# WKUP_CTRL_MMR0_WKUP_CTRL_MMR0_DDR_FREQ_CHG_43040000h register map
Vendor: Texas Instruments
Peripheral module from a debugger description file (folder am62L).
Registers are 32-bit, read-write, reset 0x0 unless marked. A register's access mark holds for its fields unless they carry their own. Offsets are as the file gives them; lines under a group give offsets from that group; [hi:lo] are bit positions; {n}, {i} and the like mark numbered series; 'fields as' and 'values as' point back to an identical list; <NAME> marks a mode.

## WKUP_CTRL_MMR0_DDR_FREQ_CHG
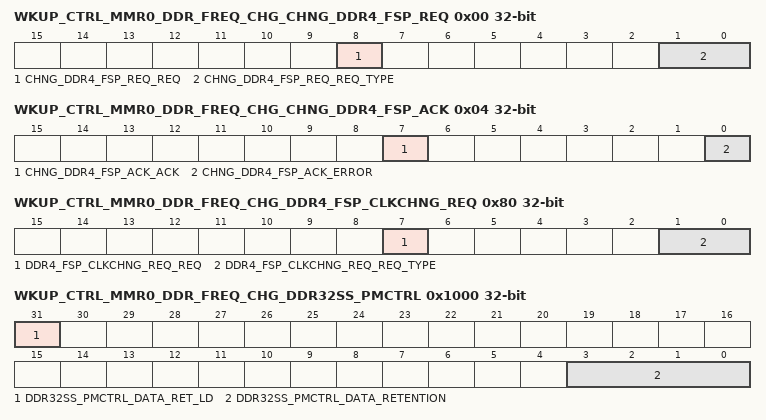
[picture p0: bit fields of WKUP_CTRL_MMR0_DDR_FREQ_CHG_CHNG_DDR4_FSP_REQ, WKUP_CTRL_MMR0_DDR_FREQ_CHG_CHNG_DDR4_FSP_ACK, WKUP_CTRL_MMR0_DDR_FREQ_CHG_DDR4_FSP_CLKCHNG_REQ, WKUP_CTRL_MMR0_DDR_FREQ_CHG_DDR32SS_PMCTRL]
0x00 WKUP_CTRL_MMR0_DDR_FREQ_CHG_CHNG_DDR4_FSP_REQ — This register is used to initiate a LPDDR4 frequency set point change to the DDR Controller
  [8] CHNG_DDR4_FSP_REQ_REQ — Initiate FSP frequency change 0 INACTIVE1 ACTIVE
  [1:0] CHNG_DDR4_FSP_REQ_REQ_TYPE — Frequency request type - Desired Frequency Set Point after switch. 0 FSP01 FSP12 FSP23 FSP3
0x04 WKUP_CTRL_MMR0_DDR_FREQ_CHG_CHNG_DDR4_FSP_ACK ro — This register is used by the DDR Controller to acknowledge the LPDDR4 frequency set point shange request
  [7] CHNG_DDR4_FSP_ACK_ACK — Frequency change acknowledge.This bit is only valid when CHNG_DDR4_FSP_REQ_req is activeIndication from the DDR Controller that the Frequency Set Point change operation is complete 0 IN_PROGRESS1 COMPLETE
  [0] CHNG_DDR4_FSP_ACK_ERROR — Frequency change errorThis bit is only valid when CHNG_DDR4_FSP_REQ_req is active. 0 SUCCESS1 ERROR
0x80 WKUP_CTRL_MMR0_DDR_FREQ_CHG_DDR4_FSP_CLKCHNG_REQ ro — This register is used by the DDR Controller to request the DDR PLL clock frequency change. This can occur as part of DDR4 initialization and training or in response to a LPDDR4 FSP change request.
  [7] DDR4_FSP_CLKCHNG_REQ_REQ — DDR Controller FSP clock change requestIndicates that the DDR controller needs the DDR clock changed to the frequency set point indicated by the req_type field. This bit is cleared when the DDR4_FSP_CLKCHNG_ACK_ack bit is set. 0 INACTIVE1 ACTIVE
  [1:0] DDR4_FSP_CLKCHNG_REQ_REQ_TYPE — Frequency request type - Desired Frequency Set Point after switch. 0 FSP01 FSP12 FSP23 FSP3
0x84 WKUP_CTRL_MMR0_DDR_FREQ_CHG_DDR4_FSP_CLKCHNG_ACK — This register is used to acknowledge a DDR PLL clock frequency change to the DDR Controller.
  [0] DDR4_FSP_CLKCHNG_ACK_ACK — DDR FSP clock change ackowledgeThis bit should be set once the DDR clock has been sucessfully changed to the value requested by DDR4_FSP_CLKCHNG_REQ_req_type. Setting this bit will clear the DDR4_FSP_CLKCHNG_REQ_req bit and the associated change request interrupt. 1 COMPLETE
0x1000 WKUP_CTRL_MMR0_DDR_FREQ_CHG_DDR32SS_PMCTRL — Control Sleep States of DDR32SS
  [31] DDR32SS_PMCTRL_DATA_RET_LD — Controls latching of the retention value 0 LATCH_CLOSED1 LATCH_OPEN
  [3:0] DDR32SS_PMCTRL_DATA_RETENTION — DDR32SS Retention: This is a fault tolerant bit field 0x06 Asserts DDRSS 'data_retention' which will Hi-Z most of the phy output pins except for CKE/RESET# All others (Default 0) : data_retention is deasserted for normal DDR32SS Operation 0 RETENTION_DEACTIVATED6 RETENTION_ACTIVATED
0x5000 WKUP_CTRL_MMR0_DDR_FREQ_CHG_USB0_PHY_CTRL — Selects the voltage option USB0 PHY
  [31] USB0_PHY_CTRL_CORE_VOLTAGE — Selects the USB PHY Core Voltage 0 DEFAULT1 RESERVED
0x5004 WKUP_CTRL_MMR0_DDR_FREQ_CHG_USB1_PHY_CTRL — Selects the voltage option USB1 PHY
  [31] USB1_PHY_CTRL_CORE_VOLTAGE — Selects the USB PHY Core Voltage 0 DEFAULT1 RESERVED
